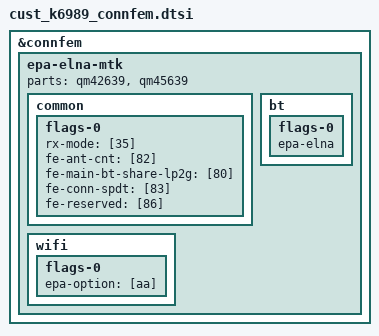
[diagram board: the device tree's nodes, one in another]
// SPDX-License-Identifier: (GPL-2.0 OR MIT)
/*
 * Copyright (C) 2020 MediaTek Inc.
 */
&connfem {
	epa-elna-mtk {
		parts = <&qm42639 &qm45639>;

		common {
			flags-0 {
				rx-mode = [35];
				fe-ant-cnt = [82];
				fe-main-bt-share-lp2g = [80];
				fe-conn-spdt = [83];
				fe-reserved = [86];
			};
		};

		wifi {
			flags-0 {
				epa-option = [aa];
				/* open-loop; */
			};
		};

		bt {
			flags-0 {
				/* choose one of: epa-elna / epa / elna / bypass */
				epa-elna;
			};
		};
	};
};
